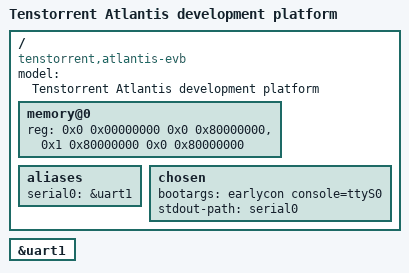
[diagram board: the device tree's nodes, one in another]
// SPDX-License-Identifier: (GPL-2.0 OR MIT)
/dts-v1/;

#include "atlantis-soc.dtsi"

/ {
	model = "Tenstorrent Atlantis development platform";
	compatible = "tenstorrent,atlantis-evb", "tenstorrent,atlantis";

	#address-cells = <2>;
	#size-cells = <2>;

	memory@0 {
		device_type = "memory";
		reg = <0x0 0x00000000 0x0 0x80000000>,
		      <0x1 0x80000000 0x0 0x80000000>;
	};

	aliases {
		serial0 = &uart1;
	};

	chosen {
		bootargs = "earlycon console=ttyS0";
		stdout-path = "serial0";
	};
};

&uart1 {
	status = "okay";
};
